# GD32A71x register map
File version: 1.0
CPU: CM7 r2p1, little endian, MPU, FPU, DSP, 4 interrupt priority bits
Registers are 32-bit, read-write, reset 0x0 unless marked. A register's access mark holds for its fields unless they carry their own. Offsets are from the block's base; [hi:lo] are bit positions; {n}, {i} and the like mark numbered series.

## STCM — Self-test control module
Base 0x40025000
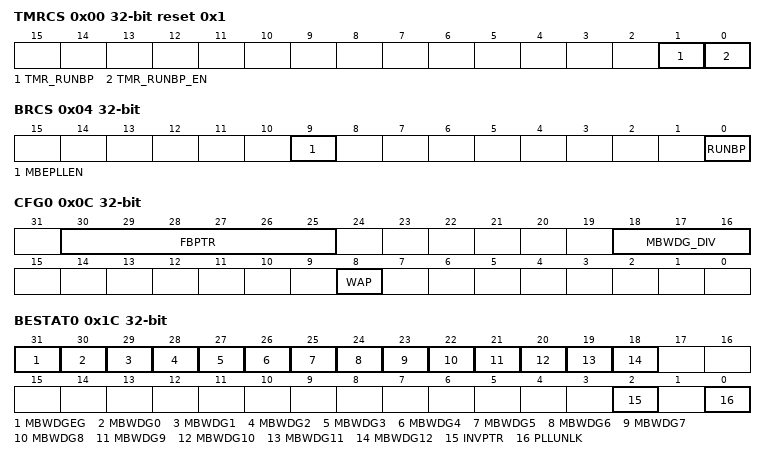
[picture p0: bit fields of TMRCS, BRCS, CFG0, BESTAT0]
0x00 TMRCS reset 0x1 — TMR control and status register
  [1] TMR_RUNBP — TMR (Triple-Modular Redundancy) state of run BIST phase
  [0] TMR_RUNBP_EN — TMR (Triple-Modular Redundancy) run BIST phase enable
0x04 BRCS — BIST running control and status register
  [9] MBEPLLEN — MBIST executed with PLL enabled
  [0] RUNBP — Run BIST phase
0x08 WPK wo — Write protection key register
  [31:0] WPK — STCM write protection key
0x0C CFG0 — Configuration register 0
  [30:25] FBPTR — First BIST pointer
  [18:16] MBWDG_DIV — MBIST watchdog clock divider
  [8] WAP — Write access protection
0x18 MBWDGT reset 0xFFFF — MBIST watchdog timer register
  [31:0] MBWDGT — MBIST watch dog timer
0x1C BESTAT0 ro — BIST error state register 0
  [31] MBWDGEG — MBIST watchdog global error state
  [30-n] MBWDG{n} (n=0..12) — MBIST partition {n} watchdog error state
  [2] INVPTR — Invalid LBIST pointer error state
  [0] PLLUNLK — PLL unlock error state
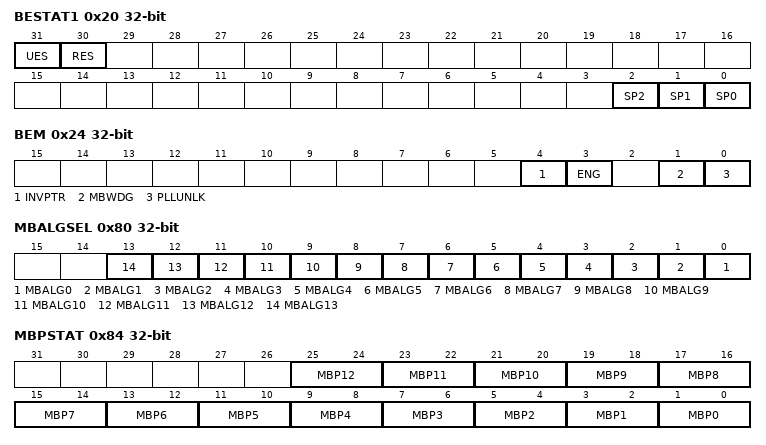
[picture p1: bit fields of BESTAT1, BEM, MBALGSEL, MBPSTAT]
0x20 BESTAT1 access per field — BIST error state register 1
  [31] UES rw — Unrecoverable error state
  [30] RES rw — Recoverable error state
  [2] SP2 ro — SMART protocol error state 2
  [1] SP1 ro — SMART protocol error state 1
  [0] SP0 ro — SMART protocol error state 0
0x24 BEM — BIST error mapping register
  [4] INVPTR — Invalid BIST pointer error mapping
  [3] ENG — Engine unrecoverable error mapping
  [1] MBWDG — MBIST watchdog error mapping
  [0] PLLUNLK — PLL unlock error mapping
0x28 BINTVL — BIST interval register
  [31:0] INTVL — BIST interval, number of HCLK cycles between BISTs execution
0x80 MBALGSEL — MBIST algorithm selection register
  [n] MBALG{n} (n=0..13) — MBIST algorithm {n} selection
0x84 MBPSTAT ro — MBIST phase state register
  [2n+1:2n] MBP{n} (n=0..12) — MBIST partition {n} state
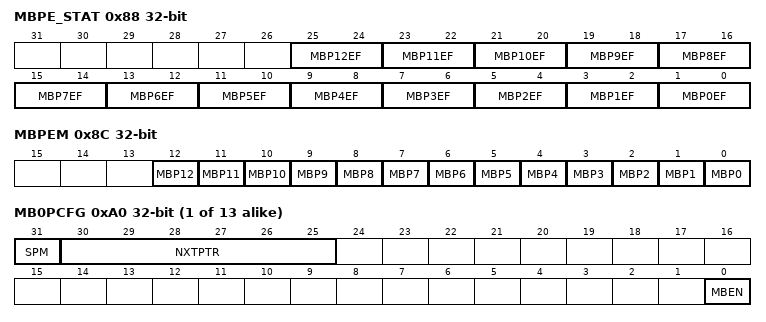
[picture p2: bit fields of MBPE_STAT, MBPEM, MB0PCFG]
0x88 MBPE_STAT ro — MBIST phase end state register
  [2n+1:2n] MBP{n}EF (n=0..12) — MBIST partition end flag {n}
0x8C MBPEM — MBIST phase error mapping register
  [n] MBP{n} (n=0..12) — mbist partition {n} unrecoverable error mapping
0x90 MBLAUNCH — MBIST phase launch register
  [2:0] MBLAUNCH — MBIST launch configuration
{0xA0+4i} MB{i}PCFG (i=0..12) — MBIST{i} phase configuration register
  [31] SPM — Serial/parallel mode
  [30:25] NXTPTR — Next LBIST or MBIST pointer
  [0] MBEN — MBIST enable

## TIMER5 — Basic timer
Base 0x40016000
Same registers: TIMER6 0x40001400
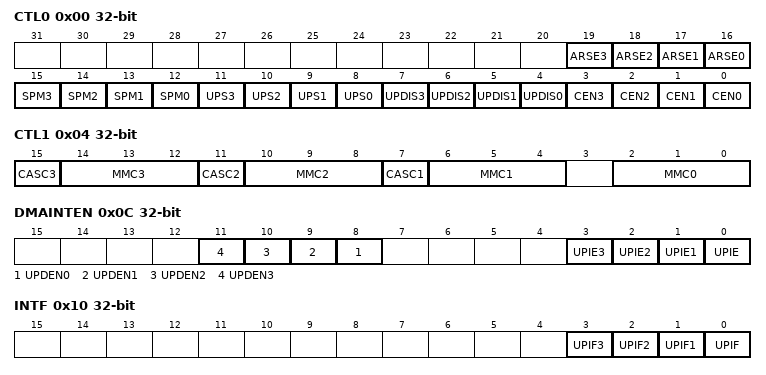
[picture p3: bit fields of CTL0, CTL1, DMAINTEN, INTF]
0x00 CTL0 — Control register 0
  [n+16] ARSE{n} (n=0..3) — Auto-reload shadow enable of channel {n}
  [15] SPM3 — Single pulse mode of channel 3
  [14] SPM2 — Single pulse mode of channel2
  [13] SPM1 — Single pulse mode of channel 1
  [12] SPM0 — Single pulse mode of channel
  [n+8] UPS{n} (n=0..3) — Update source of channel {n}
  [n+4] UPDIS{n} (n=0..3) — Update disable of channel {n}
  [n] CEN{n} (n=0..3) — Counter enable of channel {n}
0x04 CTL1 — Control register 1
  [15] CASC3 — Cascade mode of channel 2 enable
  [4n+2:4n] MMC{n} (n=0..3) — Master mode control of channel {n}
  [11] CASC2 — Cascade mode of channel 2 enable
  [7] CASC1 — Cascade mode of channel 1 enable
0x0C DMAINTEN — Interrupt enable register
  [n+8] UPDEN{n} (n=0..3) — Update DMA request enable of channel {n}
  [3] UPIE3 — Update interrupt enable of channel 3
  [2] UPIE2 — Update interrupt enable of channel 2
  [1] UPIE1 — Update interrupt enable of channel 1
  [0] UPIE — Update interrupt enable of channel 0
0x10 INTF — Interrupt flag register
  [3] UPIF3 — Update interrupt flag of channel 3
  [2] UPIF2 — Update interrupt flag of channel 2
  [1] UPIF1 — Update interrupt flag of channel 1
  [0] UPIF — Update interrupt flag of channel 0
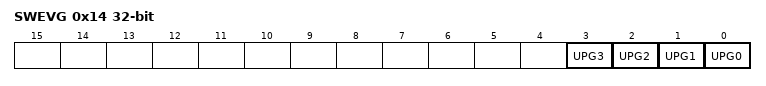
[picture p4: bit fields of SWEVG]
0x14 SWEVG wo — Software event generation register
  [3] UPG3 — Refer to UPG0
  [2] UPG2 — Refer to UPG0
  [1] UPG1 — Refer to UPG0
  [0] UPG0 — This bit can be set by software, and automatically cleared by hardware
{0x18+4i} CNT{i} (i=0..3) — Counter register
  [31:0] CNT{i} — This bit-field indicates the current counter value of channel {i}
{0x28+4i} PSC{i} (i=0..3) — Prescaler register
  [15:0] PSC{i} — Prescaler value of the counter clock of channel {i}
{0x38+4i} CAR{i} (i=0..3) — Counter auto reload register
  [31:0] CARL{i} — Counter auto reload value of channel {i}
0x48 CASCH — Cascade timer high register
  [31:0] CASCH — These bits store the high 32 bits of the 64bit counter in cascade mode
0x4C CASCL — Cascade timer low register
  [31:0] CASL — These bits store the low 32 bits of the 64bit counter in cascade mode

## WWDGT0 — Window watchdog timer
Base 0x40002C00
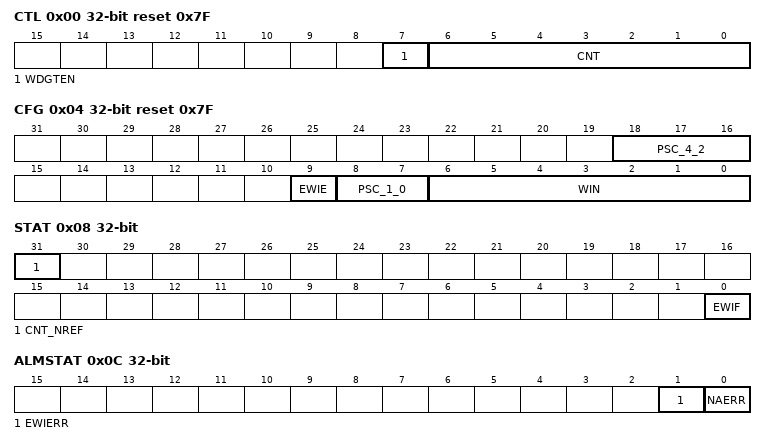
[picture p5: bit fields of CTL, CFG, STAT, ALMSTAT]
0x00 CTL reset 0x7F — Control register
  [7] WDGTEN — Start the Window watchdog timer
  [6:0] CNT — The value of the watchdog timer counter
0x04 CFG reset 0x7F — Configuration register
  [18:16] PSC_4_2 — PSC[4:2],refer to PSC[1:0] description
  [9] EWIE — Early wakeup interrupt enable
  [8:7] PSC_1_0 — Prescaler
  [6:0] WIN — The Window value
0x08 STAT access per field — Status register
  [31] CNT_NREF ro — CNT not refresh flag
  [0] EWIF rw — Early wakeup interrupt flag
0x0C ALMSTAT — ALARM Status register
  [1] EWIERR — Early wakeup interrupt cannot be generated normally error flag
  [0] NAERR — WWDGT cannot be activated error flag
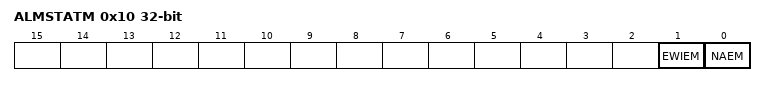
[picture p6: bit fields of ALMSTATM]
0x10 ALMSTATM — ALARM Status Mask register
  [1] EWIEM — EWIERR status mask bit
  [0] NAEM — NAERR status mask bit
